# S32K312_M7 register map
Vendor: NXP Semiconductors; File version: 1.4
CPU: CM7 r0p1, little endian, MPU, FPU, VTOR, 4 interrupt priority bits
Registers are 32-bit, read-write, reset 0x0 unless marked. A register's access mark holds for its fields unless they carry their own. Offsets are from the block's base; [hi:lo] are bit positions; {n}, {i} and the like mark numbered series; 'fields as' and 'values as' point back to an identical list.

## DCM_GPR
Base 0x402AC000; alternate view of DCM
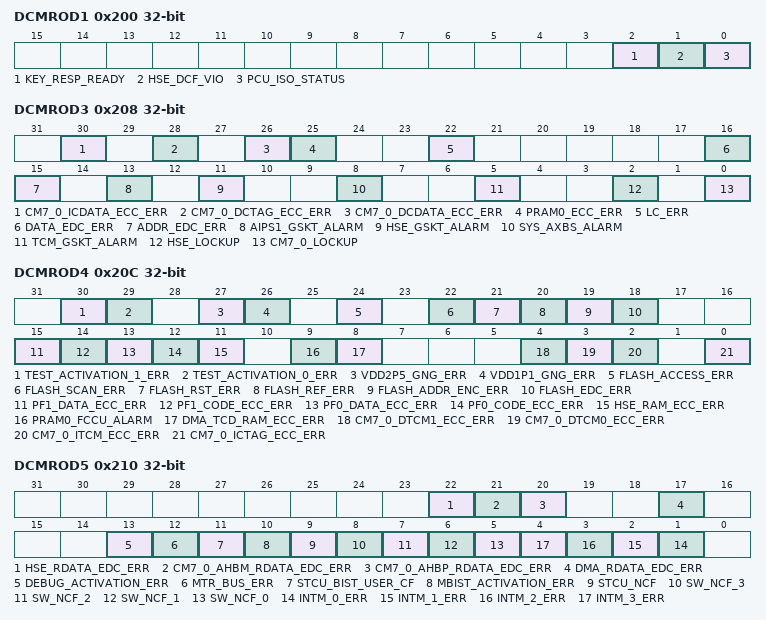
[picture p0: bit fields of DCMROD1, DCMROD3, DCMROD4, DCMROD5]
0x200 DCMROD1 write-1-clears — Read Only GPR On Destructive Reset 1
  [2] KEY_RESP_READY write-1-clears — Key Response Ready Status
    0=Key response not ready; 1=Key response ready
  [1] HSE_DCF_VIO write-1-clears — DCF Violation From HSE_B
    0=No; 1=Yes
  [0] PCU_ISO_STATUS write-1-clears — PCU Input Isolation Status On Previous Standby Entry
    0=No; 1=Yes
0x208 DCMROD3 write-1-clears — Read Only GPR On Destructive Reset 3
  [30] CM7_0_ICDATA_ECC_ERR write-1-clears — Cortex-M7_0 I-cache Data Memory
    0=No; 1=Yes
  [28] CM7_0_DCTAG_ECC_ERR write-1-clears — Cortex-M7_0 D-cache Tag ECC Error
    0=No; 1=Yes
  [26] CM7_0_DCDATA_ECC_ERR write-1-clears — Cortex-M7_0 D-cache Data Memory ECC Error
    0=No; 1=Yes
  [25] PRAM0_ECC_ERR write-1-clears — Multi-Bit ECC Error From PRAM0
    0=No; 1=Yes
  [22] LC_ERR write-1-clears — Error In Lifecycle Scanning
    0=No; 1=Yes
  [16] DATA_EDC_ERR write-1-clears — Data EDC Error
    0=No; 1=Yes
  [15] ADDR_EDC_ERR write-1-clears — Address EDC Error Status
    0=No; 1=Yes
  [13] AIPS1_GSKT_ALARM write-1-clears — AIPS1 IAHB Gasket Alarm Status. Read this bit to identify the reason of fault in case of FCCU NCF 1.
    0=No alarm indicated by AIPS1 IAHB gasket; 1=Alarm indicated by AIPS1 IAHB gasket
  [11] HSE_GSKT_ALARM write-1-clears — HSE IAHB Gasket Alarm Status
    0=No; 1=Yes
  [8] SYS_AXBS_ALARM write-1-clears — System AXBS Safety Alarm Status
    0=No; 1=Yes
  [5] TCM_GSKT_ALARM write-1-clears — TCM IAHB Gasket Monitor Alarm Status
    0=No; 1=Yes
  [2] HSE_LOCKUP write-1-clears — HSE_B Core Lockup Status
    0=No; 1=Yes
  [0] CM7_0_LOCKUP write-1-clears — Cortex-M7_0 Core Lockup Status
    0=No; 1=Yes
0x20C DCMROD4 write-1-clears — Read Only GPR On Destructive Reset 4
  [30] TEST_ACTIVATION_1_ERR write-1-clears — Accidental Partial Test Activation 1 Error
    0=No; 1=Yes
  [29] TEST_ACTIVATION_0_ERR write-1-clears — Accidental Partial Test Activation 0 Error
    0=No; 1=Yes
  [27] VDD2P5_GNG_ERR write-1-clears — Go/No-Go Indicator For VDD_HV_FLA
    0=Yes; 1=No
  [26] VDD1P1_GNG_ERR write-1-clears — Go/No-Go Indicator For VDD1PD1
    0=Yes; 1=No
  [24] FLASH_ACCESS_ERR write-1-clears — Transaction Monitor Mismatch Error From Flash Memory Controller
    0=No; 1=Yes
  [22] FLASH_SCAN_ERR write-1-clears — Flash Memory Scan Error Status
    0=No; 1=Yes
  [21] FLASH_RST_ERR write-1-clears — Flash Reset Error Status
    0=No; 1=Yes
  [20] FLASH_REF_ERR write-1-clears — Flash Memory Reference Error Status
    0=No; 1=Yes
  [19] FLASH_ADDR_ENC_ERR write-1-clears — Flash Memory Address Encode Error Status
    0=No; 1=Yes
  [18] FLASH_EDC_ERR write-1-clears — Flash Memory EDC Error Status
    0=No; 1=Yes
  [15] PF1_DATA_ECC_ERR write-1-clears — Program Flash Memory 1 Data ECC Error Status
    0=No; 1=Yes
  [14] PF1_CODE_ECC_ERR write-1-clears — Program Flash Memory 1 Code ECC Error Status
    0=No; 1=Yes
  [13] PF0_DATA_ECC_ERR write-1-clears — Program Flash Memory 0 Data ECC Error Status
    0=No; 1=Yes
  [12] PF0_CODE_ECC_ERR write-1-clears — Program Flash Memory 0 Code ECC Error Status
    0=No; 1=Yes
  [11] HSE_RAM_ECC_ERR write-1-clears — HSE_B RAM Uncorrectable ECC Status
    0=No; 1=Yes
  [9] PRAM0_FCCU_ALARM write-1-clears — PRAM0 FCCU Alarm Status
    0=No; 1=Yes
  [8] DMA_TCD_RAM_ECC_ERR write-1-clears — eDMA TCD RAM ECC Error
    0=No; 1=Yes
  [4] CM7_0_DTCM1_ECC_ERR write-1-clears — Cortex-M7_0 DTCM 1 ECC Error
    0=No; 1=Yes
  [3] CM7_0_DTCM0_ECC_ERR write-1-clears — Cortex-M7_0 DTCM 0 ECC Error
    0=No; 1=Yes
  [2] CM7_0_ITCM_ECC_ERR write-1-clears — Cortex-M7_0 ITCM ECC Error
    0=No; 1=Yes
  [0] CM7_0_ICTAG_ECC_ERR write-1-clears — Cortex-M7_0 I-cache Tag ECC Error
    0=No; 1=Yes
0x210 DCMROD5 write-1-clears — Read Only GPR On Destructive Reset 5
  [all] fields
    0=No; 1=Yes
  [22] HSE_RDATA_EDC_ERR write-1-clears — HSE_B Read Data EDC Error
  [21] CM7_0_AHBM_RDATA_EDC_ERR write-1-clears — Cortex-M7_0 AHBM Read Data EDC Error
  [20] CM7_0_AHBP_RDATA_EDC_ERR write-1-clears — Cortex-M7_0 AHBP Read Data EDC Error
  [17] DMA_RDATA_EDC_ERR write-1-clears — eDMA Read Data EDC Error
  [13] DEBUG_ACTIVATION_ERR write-1-clears — Debug Activation Error
  [12] MTR_BUS_ERR write-1-clears — MTR Bus Error
  [11] STCU_BIST_USER_CF write-1-clears — STCU2 BIST User CF
  [10] MBIST_ACTIVATION_ERR write-1-clears — MBIST Activation Error
  [9] STCU_NCF write-1-clears — STCU2 NCF Result Error
  [8] SW_NCF_3 write-1-clears — Software NCF3 Status
  [7] SW_NCF_2 write-1-clears — Software NCF2 Status
  [6] SW_NCF_1 write-1-clears — Software NCF1 Status
  [5] SW_NCF_0 write-1-clears — Software NCF 0 Status
  [n+1] INTM_{n}_ERR write-1-clears (n=0..3) — INTM_{n} Error
0x300 DCMROF1 — Read Only GPR On Functional Reset 1
{0x2FC+4i} DCMROF{i} write-1-clears (i=2..17) — Read Only GPR On Functional Reset {i}
  [31:0] DCF_SDID{i-2} write-1-clears — DCF Client SDID {i-2} Configuration
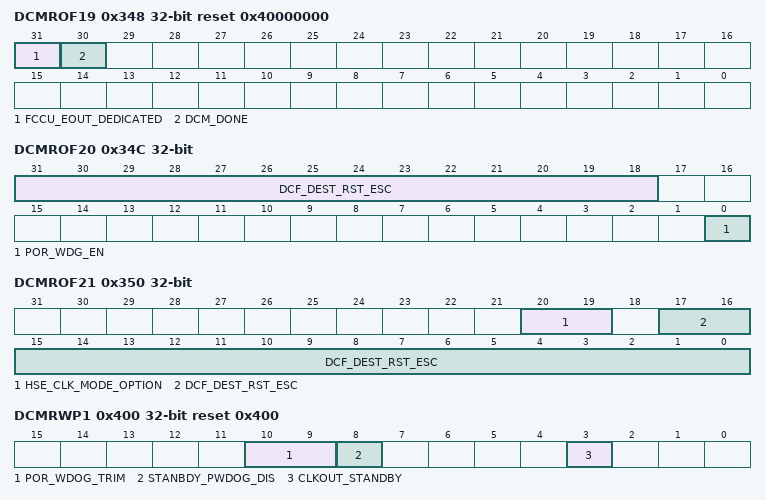
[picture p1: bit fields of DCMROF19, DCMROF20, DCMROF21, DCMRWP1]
0x348 DCMROF19 ro reset 0x40000000 — Read Only GPR On Functional Reset 19
  [31] FCCU_EOUT_DEDICATED — FCCU EOUT Status
    0=General purpose, supporting all functions; 1=Dedicated EOUT pins
  [30] DCM_DONE — Flash Memory Scanning Status
    0=Incomplete; 1=Complete
0x34C DCMROF20 ro (reset mask 0x3FFFE) — Read Only GPR On Functional Reset 20
  [31:18] DCF_DEST_RST_ESC — DCF Destructive Reset Escalation
    0=Disables; 1=Enables
  [0] POR_WDG_EN — POR Watchdog (POR_WDG) Status
    0=Disabled; 1=Enabled
0x350 DCMROF21 ro — Read Only GPR On Functional Reset 21
  [20:19] HSE_CLK_MODE_OPTION — HSE_B Clock Mode Option
    0=Option A; 1=Options C, D, E, E2, and F; 2=Option B; 3=Option B
  [17:0] DCF_DEST_RST_ESC — DCF Destructive Reset Escalation
    0=Disables; 1=Enables
0x400 DCMRWP1 reset 0x400 — Read Write GPR On POR 1
  [10:9] POR_WDOG_TRIM — POR_WDG Trim
    0=POR_WDG timeout = 06.25 ms; 1=POR_WDG timeout = 12.50 ms; 2=POR_WDG timeout = 25.00 ms; 3=POR_WDG timeout = 50.00 ms
  [8] STANBDY_PWDOG_DIS — Standby POR_WDG Disable
    0=Enables; 1=Disables
  [3] CLKOUT_STANDBY — Clockout Standby Expose Over Functional And Destructive Reset
    0=No; 1=Yes
0x408 DCMRWP3 — Read Write GPR On POR 3
  [9] DEST_RST9_AS_IPI — Destructive Reset 9
    0=Destructive reset; 1=PLL LOL interrupt
0x504 DCMRWD2 — Read Write GPR On Destructive Reset 2
  [7] EOUT_STAT_DUR_STEST — Controls the EOUT state during self-test. If this field is 0, the EOUT state changes to high Z post self-test when the chip is under reset, and if this field is 1, the EOUT state remains in Fault state until the field becomes 0.
    0=Changes to high Z; 1=Remains in Fault state
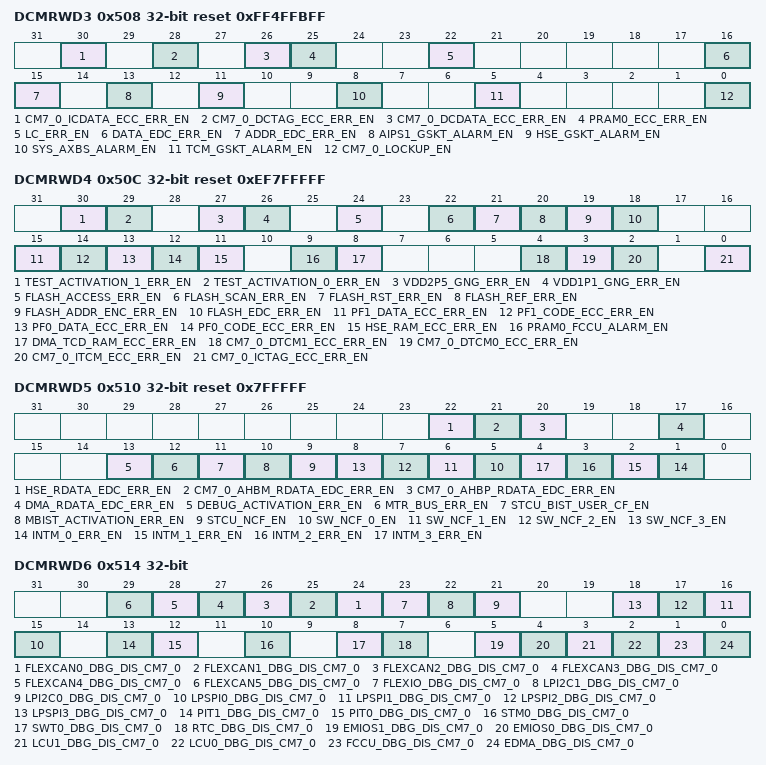
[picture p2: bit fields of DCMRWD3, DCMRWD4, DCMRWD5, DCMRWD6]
0x508 DCMRWD3 reset 0xFF4FFBFF — Read Write GPR On Destructive Reset 3
  [30] CM7_0_ICDATA_ECC_ERR_EN — Cortex-M7_0 I-cache ECC Error Enable
    0=No; 1=Yes
  [28] CM7_0_DCTAG_ECC_ERR_EN — Cortex-M7_0 D-cache Tag ECC Error Enable
    0=No; 1=Yes
  [26] CM7_0_DCDATA_ECC_ERR_EN — Cortex-M7_0 D-cache Data ECC Error Enable
    0=No; 1=Yes
  [25] PRAM0_ECC_ERR_EN — PRAM0 ECC Error Enable
    0=No; 1=Yes
  [22] LC_ERR_EN — Lifecycle Scanning Error Enable
    0=No; 1=Yes
  [16] DATA_EDC_ERR_EN — Data EDC Error Enable
    0=No; 1=Yes
  [15] ADDR_EDC_ERR_EN — Address EDC Error Enable
    0=No; 1=Yes
  [13] AIPS1_GSKT_ALARM_EN — Enable bit for enabling the fault monitoring at FCCU NCF 1 for the fault: AIPS1 IAHB gasket alarm.
    values as DCMROD3.AIPS1_GSKT_ALARM
  [11] HSE_GSKT_ALARM_EN — HSE_B Gasket Alarm Enable
    0=No; 1=Yes
  [8] SYS_AXBS_ALARM_EN — System AXBS Alarm Enable
    0=No; 1=Yes
  [5] TCM_GSKT_ALARM_EN — TCM Gasket Alarm Enable
    0=No; 1=Yes
  [0] CM7_0_LOCKUP_EN — Cortex-M7 Lockup Enable
    0=No; 1=Yes
0x50C DCMRWD4 reset 0xEF7FFFFF — Read Write GPR On Destructive Reset 4
  [30] TEST_ACTIVATION_1_ERR_EN — Test Activation 1 Error Enable
    0=No; 1=Yes
  [29] TEST_ACTIVATION_0_ERR_EN — Test Activation 0 Error Enable
    0=No; 1=Yes
  [27] VDD2P5_GNG_ERR_EN — VDD2P5 Go/Nogo Error Enable
    0=Go indication that the supply is clean; 1=No go indication that the supply is unclean and there is a fault in double-bond connection or its routing within the chip
  [26] VDD1P1_GNG_ERR_EN — VDD1PD1 Go/Nogo Error Enable
    0=Go indication that the supply is clean; 1=No go indication that the supply is unclean and there is a fault in the double-bond connection or its routing within the chip
  [24] FLASH_ACCESS_ERR_EN — Flash Memory Access Error Enable
    0=No; 1=Yes
  [22] FLASH_SCAN_ERR_EN — Flash Memory Scanning Error Enable
    0=No; 1=Yes
  [21] FLASH_RST_ERR_EN — Flash Memory Reset Error Enable
    0=No; 1=Yes
  [20] FLASH_REF_ERR_EN — Flash Memory Reference Error Encode
    0=No; 1=Yes
  [19] FLASH_ADDR_ENC_ERR_EN — Flash Memory Address Encode Error Enable
    0=No; 1=Yes
  [18] FLASH_EDC_ERR_EN — Flash Memory EDC Error Enable
    0=No; 1=Yes
  [15] PF1_DATA_ECC_ERR_EN — PF1 Data ECC Error Enable
    0=No; 1=Yes
  [14] PF1_CODE_ECC_ERR_EN — PF1 Code ECC Error Enable
    0=No; 1=Yes
  [13] PF0_DATA_ECC_ERR_EN — PF0 Data ECC Error Enable
    0=No; 1=Yes
  [12] PF0_CODE_ECC_ERR_EN — PF0 Code ECC Error Enable
    0=No; 1=Yes
  [11] HSE_RAM_ECC_ERR_EN — HSE_B RAM ECC Error Enable
    0=No; 1=Yes
  [9] PRAM0_FCCU_ALARM_EN — PRAM0 FCCU Alarm Enable
    0=No; 1=Yes
  [8] DMA_TCD_RAM_ECC_ERR_EN — eDMA TCD RAM ECC Error Enable
    0=No; 1=Yes
  [4] CM7_0_DTCM1_ECC_ERR_EN — Cortex-M7_0 DTCM 1 ECC Error Enable
    0=No; 1=Yes
  [3] CM7_0_DTCM0_ECC_ERR_EN — Cortex-M7_0 DTCM 0 ECC Error Enable
    0=No; 1=Yes
  [2] CM7_0_ITCM_ECC_ERR_EN — Cortex-M7 ITCM ECC Error Enable
    0=No; 1=Yes
  [0] CM7_0_ICTAG_ECC_ERR_EN — Cortex-M7_0 I-cache Tag ECC Error Enable
    0=No; 1=Yes
0x510 DCMRWD5 reset 0x7FFFFF — Read Write GPR On Destructive Reset 5
  [22] HSE_RDATA_EDC_ERR_EN — HSE_B Read Data EDC Error Enable
    0=No; 1=Yes
  [21] CM7_0_AHBM_RDATA_EDC_ERR_EN — Cortex-M7_0 AHBM Read Data EDC Error Enable
    0=No; 1=Yes
  [20] CM7_0_AHBP_RDATA_EDC_ERR_EN — Cortex-M7_0 AHBP Read Data EDC Error Enable
    0=No; 1=Yes
  [17] DMA_RDATA_EDC_ERR_EN — eDMA Read Data EDC Error Enable
    0=No; 1=Yes
  [13] DEBUG_ACTIVATION_ERR_EN — Debug Activation Error Enable
    0=No; 1=Yes
  [12] MTR_BUS_ERR_EN — MTR Bus Error Enable
    0=No; 1=Yes
  [11] STCU_BIST_USER_CF_EN — STCU2 BIST User CF Enable
    0=No; 1=Yes
  [10] MBIST_ACTIVATION_ERR_EN — MBIST Activation Error Enable
    0=No; 1=Yes
  [9] STCU_NCF_EN — STCU2 NCF Enable
    0=Disables; 1=Enables
  [n+5] SW_NCF_{n}_EN (n=0..3) — Software NCF {n} Enable
    0=Disables; 1=Enables
  [n+1] INTM_{n}_ERR_EN (n=0..3) — INTM {n} Error Enable
    0=No; 1=Yes
0x514 DCMRWD6 — Read Write GPR On Destructive Reset 6
  [n+24] FLEXCAN{n}_DBG_DIS_CM7_0 (n=0..5) — FlexCAN_{n} Debug Disable Cortex-M7_0
    0=Enters Debug mode; 1=Remains functional and unimpacted
  [23] FLEXIO_DBG_DIS_CM7_0 — FlexIO Debug Disable Cortex-M7_0
    0=Enters Debug mode; 1=Remains functional and unimpacted
  [22] LPI2C1_DBG_DIS_CM7_0 — LPI2C_1 Debug Disable Cortex-M7_0
    0=Enters Debug mode; 1=Remains functional and unimpacted
  [21] LPI2C0_DBG_DIS_CM7_0 — LPI2C_0 Debug Disable Cortex-M7_0
    0=Enters Debug mode; 1=Remains functional and unimpacted
  [n+15] LPSPI{n}_DBG_DIS_CM7_0 (n=0..3) — LPSPI_{n} Debug Disable Cortex-M7_0
    0=Enters Debug mode; 1=Remains functional and unimpacted
  [13] PIT1_DBG_DIS_CM7_0 — PIT_1 Debug Disable Cortex-M7_0
    0=Enters Debug mode; 1=Remains functional and unimpacted
  [12] PIT0_DBG_DIS_CM7_0 — PIT_0 Debug Disable Cortex-M7_0
    0=Enters Debug mode; 1=Remains functional and unimpacted
  [10] STM0_DBG_DIS_CM7_0 — STM_0 Debug Disable Cortex-M7_0
    0=Enters Debug mode; 1=Remains functional and unimpacted
  [8] SWT0_DBG_DIS_CM7_0 — SWT_0 Debug Disable Cortex-M7_0
    0=Enters Debug mode; 1=Remains functional and unimpacted
  [7] RTC_DBG_DIS_CM7_0 — RTC Debug Disable Cortex-M7_0
    0=Enters Debug mode; 1=Remains functional and unimpacted
  [5] EMIOS1_DBG_DIS_CM7_0 — EMIOS1 debug disable bit for CM7_0. Set this bit 1 to disable the debug of IP.
    0=eMIOS1 enters debug mode when CM7_0 enters debug mode; 1=eMIOS1 remains functional and is not impacted when CM7_0 enters debug mode
  [4] EMIOS0_DBG_DIS_CM7_0 — eMIOS_0 Debug Disable Cortex-M7_0
    0=Enters Debug mode; 1=Remains functional and unimpacted
  [3] LCU1_DBG_DIS_CM7_0 — LCU_1 Debug Disable Cortex-M7_0
    0=Enters Debug mode; 1=Remains functional and unimpacted
  [2] LCU0_DBG_DIS_CM7_0 — LCU_0 Debug Disable Cortex-M7_0
    0=Enters Debug mode; 1=Remains functional and unimpacted
  [1] FCCU_DBG_DIS_CM7_0 — FCCU Debug Disable Cortex-M7_0
    0=Enters Debug mode; 1=Remains functional and unimpacted
  [0] EDMA_DBG_DIS_CM7_0 — eDMA Debug Disable Cortex-M7_0
    0=Enters Debug mode; 1=Remains functional and unimpacted
0x518 DCMRWD7 — Read Write GPR On Destructive Reset 7
  [0] I3C_DBG_DIS_CM7_0 — I3C Debug Disable Cortex-M7_0
    0=Enters Debug mode; 1=Remains functional and unimpacted
0x51C DCMRWD8 — Read Write GPR On Destructive Reset 8
0x520 DCMRWD9 — Read Write GPR On Destructive Reset 9
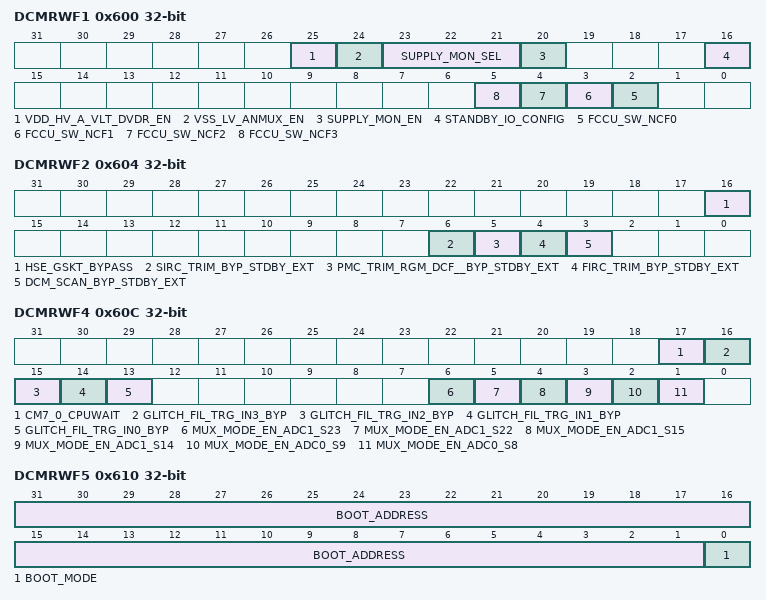
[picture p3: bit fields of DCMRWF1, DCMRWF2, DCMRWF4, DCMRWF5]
0x600 DCMRWF1 — Read Write GPR On Functional Reset 1
  [25] VDD_HV_A_VLT_DVDR_EN — VDD_HV_A Voltage Divider Enable
    0=Disables; 1=Enables
  [24] VSS_LV_ANMUX_EN — VSS_LV Monitoring Enable
    0=Disables; 1=Enables
  [23:21] SUPPLY_MON_SEL — Supply Monitoring Select
    0=VDD_HV_A_DIV; 1=VDD_HV_B_DIV; 2=VDD_1.5_DIV; 3=VDD_2.5_OSC; 4=VDD1.1_PD1_HOT_POINT; 5=VDD1.1_PD1_COLD_POINT; 6=VDD1.1_PLL; 7=VDD1.1_PD0
  [20] SUPPLY_MON_EN — Supply Monitoring Enable
    0=Disables; 1=Enables
  [16] STANDBY_IO_CONFIG — Standby I/O Configuration
    0=Standby I/O configuration standby entry; 1=Standby I/O configuration standby exit
  [n+2] FCCU_SW_NCF{n} (n=0..3) — FCCU Software NCF {n}
    0=Not generated; 1=Generated
0x604 DCMRWF2 — Read Write GPR On Functional Reset 2
  [16] HSE_GSKT_BYPASS — HSE_B Gasket Bypass
    0=Bypass configuration controlled by the DCF client; 1=Bypassed out of standby
  [6] SIRC_TRIM_BYP_STDBY_EXT — SIRC Trim Bypass Standby Exit
    0=Not bypassed; 1=Bypassed
  [5] PMC_TRIM_RGM_DCF__BYP_STDBY_EXT — PMC Trim MC_RGM DCF Bypass Standby Exit
    0=Not bypassed; 1=Bypassed
  [4] FIRC_TRIM_BYP_STDBY_EXT — FIRC Trim Bypass Standby Exit
    0=Not bypassed; 1=Bypassed
  [3] DCM_SCAN_BYP_STDBY_EXT — DCM Scan Bypass Standby Exit
    0=Not bypassed; 1=Bypassed
0x60C DCMRWF4 — Read Write GPR On Functional Reset 4
  [17] CM7_0_CPUWAIT — Cortex-M7_0 CPU Wait
    0=Disables CPUWAIT for Cortex-M7_0; 1=Places Cortex-M7_0 in Wait mode using CPUWAIT
  [16] GLITCH_FIL_TRG_IN3_BYP — Glitch Filter TRGMUX Input 3 Bypass
    0=Enables glitch filter on TRGMUX input 60; 1=Bypasses glitch filter on TRGMUX input 60
  [15] GLITCH_FIL_TRG_IN2_BYP — Glitch Filter TRGMUX Input 2 Bypass
    0=Enables glitch filter on TRGMUX input 61; 1=Bypasses glitch filter on TRGMUX input 61
  [14] GLITCH_FIL_TRG_IN1_BYP — Glitch Filter TRGMUX Input 1 Bypass
    0=Enables glitch filter on TRGMUX input 62; 1=Bypasses glitch filter on TRGMUX input 62
  [13] GLITCH_FIL_TRG_IN0_BYP — Glitch Filter TRGMUX Input 0 Bypass
    0=Enables glitch filter on TRGMUX input 63; 1=Bypasses glitch filter on TRGMUX input 63
  [6] MUX_MODE_EN_ADC1_S23 — Mux Mode Enable ADC_1 Standard Channel 23
    0=Selects GPIO_125 as ADC1_S23; 1=Selects GPIO_146 as ADC1_S23
  [5] MUX_MODE_EN_ADC1_S22 — Mux Mode Enable ADC_1 Standard Channel 22
    0=Selects GPIO_124 as ADC1_S22; 1=Selects GPIO_145 as ADC1_S22
  [4] MUX_MODE_EN_ADC1_S15 — Mux Mode Enable ADC_1 Standard Channel 15
    0=Selects GPIO_4 as ADC1_S15; 1=Selects GPIO_33 as ADC1_S15
  [3] MUX_MODE_EN_ADC1_S14 — Mux Mode Enable ADC_1 Standard Channel 14
    0=Selects GPIO_69 as ADC1_S14; 1=Selects GPIO_32 as ADC1_S14
  [2] MUX_MODE_EN_ADC0_S9 — Mux Mode Enable ADC_0 Standard Channel 9
    0=Selects GPIO_1 as ADC0_S9; 1=Selects GPIO_46 as ADC0_S9
  [1] MUX_MODE_EN_ADC0_S8 — Mux Mode Enable ADC_0 Standard Channel 8
    0=Selects GPIO_0 as ADC0_S8; 1=Selects GPIO_45 as ADC0_S8
0x610 DCMRWF5 reset not defined — Read Write GPR On Functional Reset 5
  [31:1] BOOT_ADDRESS
  [0] BOOT_MODE
    0=Normal; 1=Fast Standby
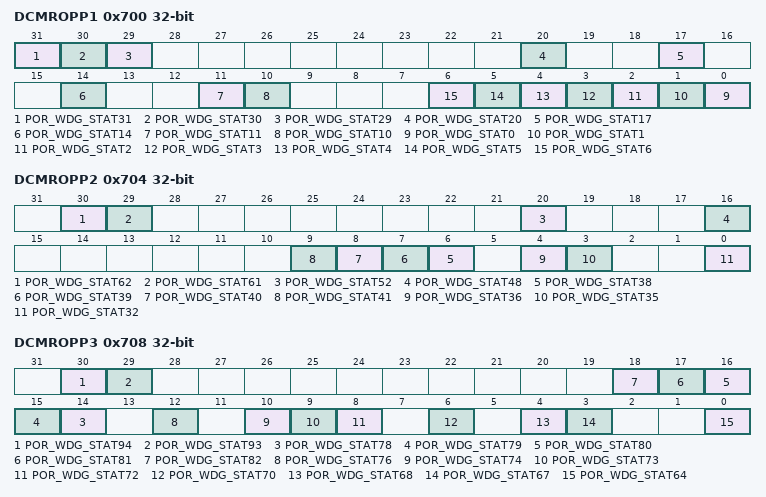
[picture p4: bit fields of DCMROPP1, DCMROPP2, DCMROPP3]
0x700 DCMROPP1 write-1-clears — Read Only GPR On PMCPOR Reset 1
  [31] POR_WDG_STAT31 write-1-clears — POR_WDG Status 31
    0=Event not detected or no reset event arrived; 1=Event detected
  [30] POR_WDG_STAT30 write-1-clears — POR_WDG Status 30
    0=Not acknowledged; 1=Acknowledged
  [29] POR_WDG_STAT29 write-1-clears — POR_WDG Status 29
    0=Active; 1=Inactive
  [20] POR_WDG_STAT20 write-1-clears — POR_WDG Status 20
    0=Inactive; 1=Active
  [17] POR_WDG_STAT17 write-1-clears — POR_WDG Status 10
    0=Inactive; 1=Active
  [14] POR_WDG_STAT14 write-1-clears — POR_WDG Status 9
    0=Inactive; 1=Active
  [11] POR_WDG_STAT11 write-1-clears — POR_WDG Status 8
    0=Inactive; 1=Active
  [10] POR_WDG_STAT10 write-1-clears — POR_WDG Status 7
    0=Inactive; 1=Active
  [n] POR_WDG_STAT{n} write-1-clears (n=0..6) — POR_WDG Status {n}
    0=Inactive; 1=Active
0x704 DCMROPP2 write-1-clears — Read Only GPR On PMCPOR Reset 2
  [all] fields
    0=0; 1=1
  [30] POR_WDG_STAT62 write-1-clears — POR_WDG Status 62
  [29] POR_WDG_STAT61 write-1-clears — POR_WDG Status 61
  [20] POR_WDG_STAT52 write-1-clears — POR_WDG Status 52
  [16] POR_WDG_STAT48 write-1-clears — POR_WDG Status 48
  [n-32] POR_WDG_STAT{n} write-1-clears (n=38..41) — POR_WDG Status {n}
  [4] POR_WDG_STAT36 write-1-clears — POR_WDG Status 36
  [3] POR_WDG_STAT35 write-1-clears — POR_WDG Status 35
  [0] POR_WDG_STAT32 write-1-clears — POR_WDG Status 32
0x708 DCMROPP3 write-1-clears — Read Only GPR On PMCPOR Reset 3
  [all] fields
    0=0; 1=1
  [30] POR_WDG_STAT94 write-1-clears — POR_WDG Status 94
  [29] POR_WDG_STAT93 write-1-clears — POR_WDG Status 93
  [n-64] POR_WDG_STAT{n} write-1-clears (n=78..82) — POR_WDG Status {n}
  [12] POR_WDG_STAT76 write-1-clears — POR_WDG Status 76
  [10] POR_WDG_STAT74 write-1-clears — POR_WDG Status 74
  [9] POR_WDG_STAT73 write-1-clears — POR_WDG Status 73
  [8] POR_WDG_STAT72 write-1-clears — POR_WDG Status 72
  [6] POR_WDG_STAT70 write-1-clears — POR_WDG Status 70
  [4] POR_WDG_STAT68 write-1-clears — POR_WDG Status 68
  [3] POR_WDG_STAT67 write-1-clears — POR_WDG Status 67
  [0] POR_WDG_STAT64 write-1-clears — POR_WDG Status 64
0x70C DCMROPP4 write-1-clears — Read Only GPR On PMCPOR Reset 4
  [0] POR_WDG_STAT96 write-1-clears — POR_WDG Status
    0=Inactive; 1=Active (detected a stuck scenario and raised the chip POR event)
